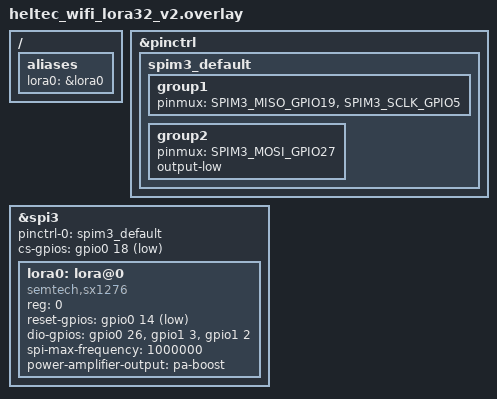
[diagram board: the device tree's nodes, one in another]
/*
 * Copyright (c) 2022 Gaël PORTAY
 *
 * SPDX-License-Identifier: Apache-2.0
 */

/ {
	aliases {
		lora0 = &lora0;
	};
};

&pinctrl {
	spim3_default: spim3_default {
		group1 {
			pinmux = <SPIM3_MISO_GPIO19>,
				 <SPIM3_SCLK_GPIO5>;
		};
		group2 {
			pinmux = <SPIM3_MOSI_GPIO27>;
			output-low;
		};
	};
};

&spi3 {
	#address-cells = <1>;
	#size-cells = <0>;
	status = "okay";
	pinctrl-0 = <&spim3_default>;
	pinctrl-names = "default";
	cs-gpios = <&gpio0 18 GPIO_ACTIVE_LOW>;
	lora0: lora@0 {
		compatible = "semtech,sx1276";
		reg = <0>;
		reset-gpios = <&gpio0 14 GPIO_ACTIVE_LOW>;
		dio-gpios =
			/* SX1276 D0 -> GPIO26 */
			<&gpio0 26 (GPIO_PULL_DOWN | GPIO_ACTIVE_HIGH)>,
			/* SX1276 D1 -> GPIO35 */
			<&gpio1 3 (GPIO_PULL_DOWN | GPIO_ACTIVE_HIGH)>,
			/* SX1276 D1 -> GPIO34 */
			<&gpio1 2 (GPIO_PULL_DOWN | GPIO_ACTIVE_HIGH)>;
		spi-max-frequency = <1000000>;
		power-amplifier-output = "pa-boost";
	};
};
